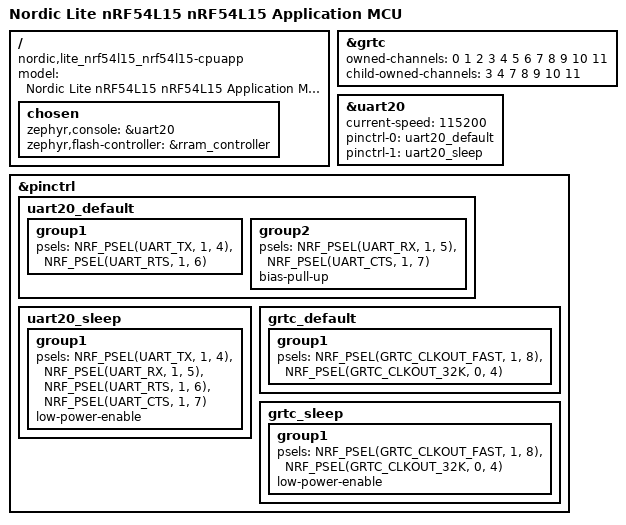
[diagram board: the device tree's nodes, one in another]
/*
 * Copyright (c) 2025 Nordic Semiconductor ASA
 *
 * SPDX-License-Identifier: Apache-2.0
 */

/ {
	compatible = "nordic,lite_nrf54l15_nrf54l15-cpuapp";
	model = "Nordic Lite nRF54L15 nRF54L15 Application MCU";

	chosen {
		zephyr,console = &uart20;
		zephyr,flash-controller = &rram_controller;
	};
};


&grtc {
	owned-channels = <0 1 2 3 4 5 6 7 8 9 10 11>;
	/* Channels 7-11 reserved for Zero Latency IRQs, 3-4 for FLPR */
	child-owned-channels = <3 4 7 8 9 10 11>;
	status = "okay";
};

/* To be removed when we have our own logging backend */
&uart20 {
	current-speed = <115200>;
	pinctrl-0 = <&uart20_default>;
	pinctrl-1 = <&uart20_sleep>;
	pinctrl-names = "default", "sleep";
	status = "okay";
};

&pinctrl {
	/* Used for logging for now */
	/omit-if-no-ref/ uart20_default: uart20_default {
		group1 {
			psels = <NRF_PSEL(UART_TX, 1, 4)>,
				<NRF_PSEL(UART_RTS, 1, 6)>;
		};
		group2 {
			psels = <NRF_PSEL(UART_RX, 1, 5)>,
				<NRF_PSEL(UART_CTS, 1, 7)>;
			bias-pull-up;
		};
	};

	/omit-if-no-ref/ uart20_sleep: uart20_sleep {
		group1 {
			psels = <NRF_PSEL(UART_TX, 1, 4)>,
				<NRF_PSEL(UART_RX, 1, 5)>,
				<NRF_PSEL(UART_RTS, 1, 6)>,
				<NRF_PSEL(UART_CTS, 1, 7)>;
			low-power-enable;
		};
	};

	/omit-if-no-ref/ grtc_default: grtc_default {
		group1 {
			psels = <NRF_PSEL(GRTC_CLKOUT_FAST, 1, 8)>,
				<NRF_PSEL(GRTC_CLKOUT_32K, 0, 4)>;
		};
	};

	/omit-if-no-ref/ grtc_sleep: grtc_sleep {
		group1 {
			psels = <NRF_PSEL(GRTC_CLKOUT_FAST, 1, 8)>,
				<NRF_PSEL(GRTC_CLKOUT_32K, 0, 4)>;
			low-power-enable;
		};
	};
};
